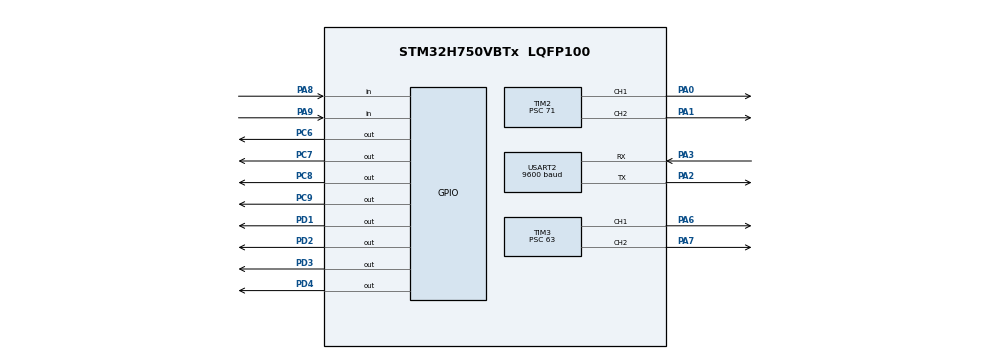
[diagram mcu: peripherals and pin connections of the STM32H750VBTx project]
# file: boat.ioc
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Mcu.Family=STM32H7
Mcu.Name=STM32H750VBTx
Mcu.Package=LQFP100
NVIC.PriorityGroup=NVIC_PRIORITYGROUP_4
NVIC.USART2_IRQn=true\:0\:0\:false\:false\:true\:true\:true
PA0.Signal=S_TIM2_CH1
PA1.Signal=S_TIM2_CH2
PA2.Mode=Asynchronous
PA2.Signal=USART2_TX
PA3.Mode=Asynchronous
PA3.Signal=USART2_RX
PA6.Signal=S_TIM3_CH1
PA7.Signal=S_TIM3_CH2
PA8.Signal=GPIO_Input
PA9.Signal=GPIO_Input
PC6.Signal=GPIO_Output
PC7.Signal=GPIO_Output
PC8.Signal=GPIO_Output
PC9.Signal=GPIO_Output
PD1.Signal=GPIO_Output
PD2.Signal=GPIO_Output
PD3.Signal=GPIO_Output
PD4.Signal=GPIO_Output
PH0-OSC_IN\ (PH0).Mode=HSE-External-Oscillator
PH0-OSC_IN\ (PH0).Signal=RCC_OSC_IN
PH1-OSC_OUT\ (PH1).Mode=HSE-External-Oscillator
PH1-OSC_OUT\ (PH1).Signal=RCC_OSC_OUT
ProjectManager.HeapSize=0x200
ProjectManager.StackSize=0x400
ProjectManager.TargetToolchain=MDK-ARM V5
RCC.ADCFreq_Value=129000000
RCC.APB1Freq_Value=64000000
RCC.APB2Freq_Value=64000000
RCC.APB3Freq_Value=64000000
RCC.APB4Freq_Value=64000000
RCC.CortexFreq_Value=64000000
RCC.DIVM1=1
RCC.DIVN1=27
RCC.DIVP1=6
RCC.HCLKFreq_Value=64000000
RCC.HSE_VALUE=25000000
RCC.PLLFRACN=0
RCC.SYSCLKFreq_VALUE=64000000
RCC.USBFreq_Value=864000000
SH.S_TIM2_CH1.0=TIM2_CH1,PWM Generation1 CH1
SH.S_TIM2_CH2.0=TIM2_CH2,PWM Generation2 CH2
SH.S_TIM3_CH1.0=TIM3_CH1,PWM Generation1 CH1
SH.S_TIM3_CH2.0=TIM3_CH2,PWM Generation2 CH2
TIM2.AutoReloadPreload=TIM_AUTORELOAD_PRELOAD_ENABLE
TIM2.Channel-PWM\ Generation1\ CH1=TIM_CHANNEL_1
TIM2.Channel-PWM\ Generation2\ CH2=TIM_CHANNEL_2
TIM2.Period=1999
TIM2.Prescaler=71
TIM3.AutoReloadPreload=TIM_AUTORELOAD_PRELOAD_ENABLE
TIM3.Channel-PWM\ Generation1\ CH1=TIM_CHANNEL_1
TIM3.Channel-PWM\ Generation2\ CH2=TIM_CHANNEL_2
TIM3.Period=499
TIM3.Prescaler=63
USART2.BaudRate=9600
USART2.VirtualMode-Asynchronous=VM_ASYNC
VP_TIM2_VS_ClockSourceINT.Mode=Internal
VP_TIM3_VS_ClockSourceINT.Mode=Internal
board=custom

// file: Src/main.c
/* USER CODE BEGIN Header */
/**
  ******************************************************************************
  * @file           : main.c
  * @brief          : Main program body
  ******************************************************************************
  * @attention
  *
  * <h2><center>&copy; Copyright (c) 2021 STMicroelectronics.
  * All rights reserved.</center></h2>
  *
  * This software component is licensed by ST under BSD 3-Clause license,
  * the "License"; You may not use this file except in compliance with the
  * License. You may obtain a copy of the License at:
  *                        opensource.org/licenses/BSD-3-Clause
  *
  ******************************************************************************
  */
/* USER CODE END Header */

#include "main.h"
#include "tim.h"
#include "usart.h"
#include "gpio.h"

/* USER CODE BEGIN Includes */
#include "move.h"
/* USER CODE END Includes */

/* USER CODE BEGIN PV */
uint8_t Rx_dat=0;
/* USER CODE END PV */

void SystemClock_Config(void);

int main(void)
{

  /* MCU Configuration--------------------------------------------------------*/

  /* Reset of all peripherals, Initializes the Flash interface and the Systick. */
  HAL_Init();

  /* Configure the system clock */
  SystemClock_Config();

  /* Initialize all configured peripherals */
  MX_GPIO_Init();
  MX_TIM2_Init();
  MX_TIM3_Init();
  MX_USART2_UART_Init();
  /* USER CODE BEGIN 2 */
  dir_init();
  HAL_TIM_PWM_Start(&htim3, TIM_CHANNEL_1);
  HAL_TIM_PWM_Start(&htim3, TIM_CHANNEL_2);
  HAL_TIM_PWM_Start(&htim2, TIM_CHANNEL_1);
  HAL_TIM_PWM_Start(&htim2, TIM_CHANNEL_2);
  HAL_UART_Receive_IT(&huart2,&Rx_dat,1);   //在main中第一次调用中断接收函数
  /* USER CODE END 2 */

  /* Infinite loop */
  while (1)
  {
	//right();
    /* USER CODE BEGIN 3 */
	 /* straight();
	  HAL_Delay(1000);
	  left();
	  HAL_Delay(1000);
	  straight();
	  HAL_Delay(1000);
	  right();
	  HAL_Delay(1000);
	  */
  }
  /* USER CODE END 3 */
}

void SystemClock_Config(void)
{
  RCC_OscInitTypeDef RCC_OscInitStruct = {0};
  RCC_ClkInitTypeDef RCC_ClkInitStruct = {0};
  RCC_PeriphCLKInitTypeDef PeriphClkInitStruct = {0};

  /** Supply configuration update enable
  */
  HAL_PWREx_ConfigSupply(PWR_LDO_SUPPLY);
  /** Configure the main internal regulator output voltage
  */
  __HAL_PWR_VOLTAGESCALING_CONFIG(PWR_REGULATOR_VOLTAGE_SCALE3);

  while(!__HAL_PWR_GET_FLAG(PWR_FLAG_VOSRDY)) {}
  /** Initializes the CPU, AHB and APB busses clocks
  */
  RCC_OscInitStruct.OscillatorType = RCC_OSCILLATORTYPE_HSI;
  RCC_OscInitStruct.HSIState = RCC_HSI_DIV1;
  RCC_OscInitStruct.HSICalibrationValue = RCC_HSICALIBRATION_DEFAULT;
  RCC_OscInitStruct.PLL.PLLState = RCC_PLL_NONE;
  if (HAL_RCC_OscConfig(&RCC_OscInitStruct) != HAL_OK)
  {
    Error_Handler();
  }
  /** Initializes the CPU, AHB and APB busses clocks
  */
  RCC_ClkInitStruct.ClockType = RCC_CLOCKTYPE_HCLK|RCC_CLOCKTYPE_SYSCLK
                              |RCC_CLOCKTYPE_PCLK1|RCC_CLOCKTYPE_PCLK2
                              |RCC_CLOCKTYPE_D3PCLK1|RCC_CLOCKTYPE_D1PCLK1;
  RCC_ClkInitStruct.SYSCLKSource = RCC_SYSCLKSOURCE_HSI;
  RCC_ClkInitStruct.SYSCLKDivider = RCC_SYSCLK_DIV1;
  RCC_ClkInitStruct.AHBCLKDivider = RCC_HCLK_DIV1;
  RCC_ClkInitStruct.APB3CLKDivider = RCC_APB3_DIV1;
  RCC_ClkInitStruct.APB1CLKDivider = RCC_APB1_DIV1;
  RCC_ClkInitStruct.APB2CLKDivider = RCC_APB2_DIV1;
  RCC_ClkInitStruct.APB4CLKDivider = RCC_APB4_DIV1;

  if (HAL_RCC_ClockConfig(&RCC_ClkInitStruct, FLASH_LATENCY_0) != HAL_OK)
  {
    Error_Handler();
  }
  PeriphClkInitStruct.PeriphClockSelection = RCC_PERIPHCLK_USART2;
  PeriphClkInitStruct.Usart234578ClockSelection = RCC_USART234578CLKSOURCE_D2PCLK1;
  if (HAL_RCCEx_PeriphCLKConfig(&PeriphClkInitStruct) != HAL_OK)
  {
    Error_Handler();
  }
}

void Error_Handler(void)
{
}

/************************ (C) COPYRIGHT STMicroelectronics *****END OF FILE****/
